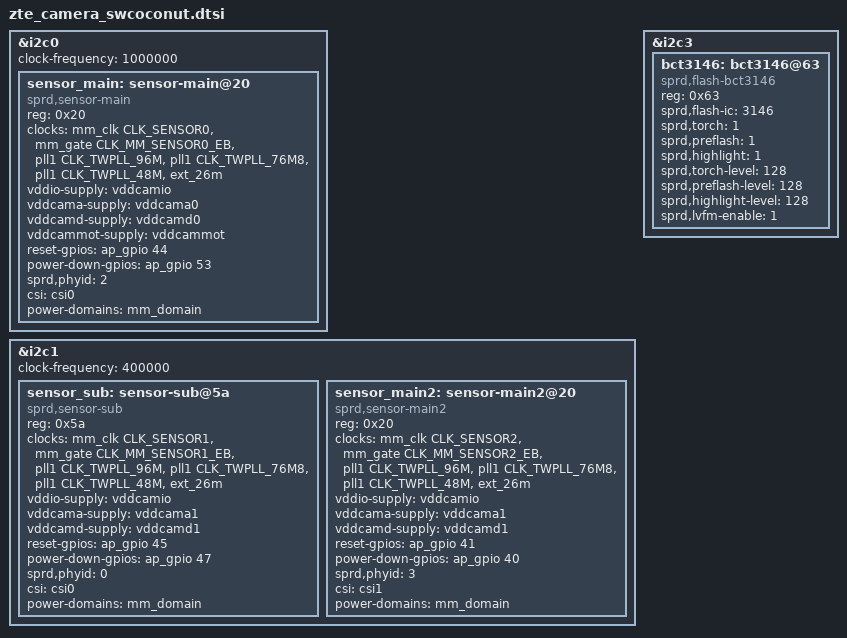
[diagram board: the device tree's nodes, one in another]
&i2c0 {
	status = "okay";
	clock-frequency = <1000000>;
	#address-cells = <1>;
	#size-cells = <0>;

	sensor_main: sensor-main@20 {
		compatible = "sprd,sensor-main";
		reg = <0x20>;
		clock-names = "clk_src","sensor_eb",
			"clk_96m","clk_76m8",
			"clk_48m","clk_26m";
		clocks = <&mm_clk CLK_SENSOR0>,<&mm_gate CLK_MM_SENSOR0_EB>,
				<&pll1 CLK_TWPLL_96M>,<&pll1 CLK_TWPLL_76M8>,
				<&pll1 CLK_TWPLL_48M>,<&ext_26m>;
		vddio-supply = <&vddcamio>;
		vddcama-supply = <&vddcama0>;
		vddcamd-supply = <&vddcamd0>;
		vddcammot-supply = <&vddcammot>;
		reset-gpios = <&ap_gpio 44 0>;
		power-down-gpios = <&ap_gpio 53 0>; /*cif*/
		sprd,phyid = <2>;
		csi = <&csi0>;
		power-domains = <&mm_domain>;
	};
};

&i2c1 {
	status = "okay";
	clock-frequency = <400000>;
	#address-cells = <1>;
	#size-cells = <0>;

	sensor_sub: sensor-sub@5a {
		compatible = "sprd,sensor-sub";
		reg = <0x5a>;
		clock-names = "clk_src","sensor_eb",
			"clk_96m","clk_76m8",
			"clk_48m","clk_26m";
		clocks = <&mm_clk CLK_SENSOR1>,<&mm_gate CLK_MM_SENSOR1_EB>,
				<&pll1 CLK_TWPLL_96M>,<&pll1 CLK_TWPLL_76M8>,
				<&pll1 CLK_TWPLL_48M>,<&ext_26m>;
		vddio-supply = <&vddcamio>;
		vddcama-supply = <&vddcama1>;
		vddcamd-supply = <&vddcamd1>;
		reset-gpios = <&ap_gpio 45 0>;
		power-down-gpios = <&ap_gpio 47 0>;
		sprd,phyid = <0>;
		csi = <&csi0>;
		power-domains = <&mm_domain>;
	};

	sensor_main2: sensor-main2@20 {
		compatible = "sprd,sensor-main2";
		reg = <0x20>;
		clock-names = "clk_src","sensor_eb",
			"clk_96m","clk_76m8",
			"clk_48m","clk_26m";
		clocks = <&mm_clk CLK_SENSOR2>,<&mm_gate CLK_MM_SENSOR2_EB>,
				<&pll1 CLK_TWPLL_96M>,<&pll1 CLK_TWPLL_76M8>,
				<&pll1 CLK_TWPLL_48M>,<&ext_26m>;
		vddio-supply = <&vddcamio>;
		vddcama-supply = <&vddcama1>;
		vddcamd-supply = <&vddcamd1>;
		reset-gpios = <&ap_gpio 41 0>;
		power-down-gpios = <&ap_gpio 40 0>;
	/*	mipi-switch-en-gpios = <&ap_gpio 55 0>;*/
	/*	mipi-switch-mode-gpios = <&ap_gpio 8 0>;*/
		sprd,phyid = <3>;
		csi = <&csi1>;
		power-domains = <&mm_domain>;
	};
};

&i2c3 {
	status = "okay";
	#address-cells = <1>;
	#size-cells = <0>;

	bct3146: bct3146@63 {
		compatible = "sprd,flash-bct3146";
		reg = <0x63>;
		sprd,flash-ic = <3146>;
		sprd,torch = <1>;
		sprd,preflash = <1>;
		sprd,highlight = <1>;
		sprd,torch-level = <128>;
		sprd,preflash-level = <128>;
		sprd,highlight-level = <128>;
		sprd,lvfm-enable = <1>;
	};
};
